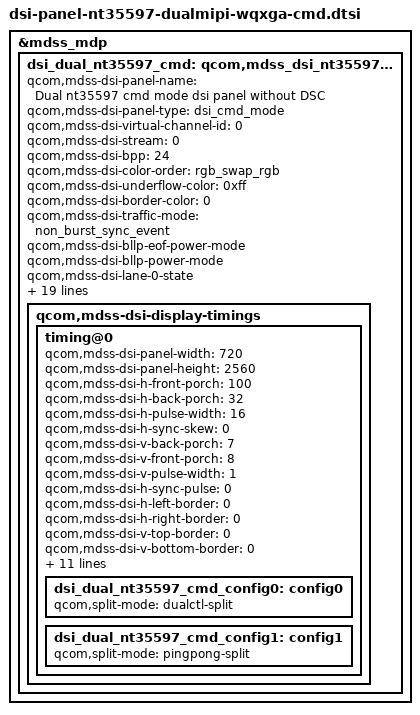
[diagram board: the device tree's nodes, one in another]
/* Copyright (c) 2015-2017, The Linux Foundation. All rights reserved.
 *
 * This program is free software; you can redistribute it and/or modify
 * it under the terms of the GNU General Public License version 2 and
 * only version 2 as published by the Free Software Foundation.
 *
 * This program is distributed in the hope that it will be useful,
 * but WITHOUT ANY WARRANTY; without even the implied warranty of
 * MERCHANTABILITY or FITNESS FOR A PARTICULAR PURPOSE.  See the
 * GNU General Public License for more details.
 */

&mdss_mdp {
	dsi_dual_nt35597_cmd: qcom,mdss_dsi_nt35597_wqxga_cmd{
		qcom,mdss-dsi-panel-name =
			"Dual nt35597 cmd mode dsi panel without DSC";
		qcom,mdss-dsi-panel-type = "dsi_cmd_mode";
		qcom,mdss-dsi-virtual-channel-id = <0>;
		qcom,mdss-dsi-stream = <0>;
		qcom,mdss-dsi-bpp = <24>;
		qcom,mdss-dsi-color-order = "rgb_swap_rgb";
		qcom,mdss-dsi-underflow-color = <0xff>;
		qcom,mdss-dsi-border-color = <0>;
		qcom,mdss-dsi-traffic-mode = "non_burst_sync_event";
		qcom,mdss-dsi-bllp-eof-power-mode;
		qcom,mdss-dsi-bllp-power-mode;
		qcom,mdss-dsi-lane-0-state;
		qcom,mdss-dsi-lane-1-state;
		qcom,mdss-dsi-lane-2-state;
		qcom,mdss-dsi-lane-3-state;
		qcom,adjust-timer-wakeup-ms = <1>;
		qcom,mdss-dsi-reset-sequence = <1 10>, <0 10>, <1 10>;
		qcom,mdss-pan-physical-width-dimension = <74>;
		qcom,mdss-pan-physical-height-dimension = <131>;
		qcom,mdss-dsi-t-clk-post = <0x0d>;
		qcom,mdss-dsi-t-clk-pre = <0x2d>;
		qcom,mdss-dsi-bl-max-level = <4095>;
		qcom,mdss-dsi-dma-trigger = "trigger_sw";
		qcom,mdss-dsi-mdp-trigger = "none";
		qcom,mdss-dsi-te-pin-select = <1>;
		qcom,mdss-dsi-wr-mem-start = <0x2c>;
		qcom,mdss-dsi-wr-mem-continue = <0x3c>;
		qcom,mdss-dsi-te-dcs-command = <1>;
		qcom,mdss-dsi-te-check-enable;
		qcom,mdss-dsi-te-using-te-pin;
		qcom,ulps-enabled;

		qcom,mdss-dsi-display-timings {
			timing@0{
				qcom,mdss-dsi-panel-width = <720>;
				qcom,mdss-dsi-panel-height = <2560>;
				qcom,mdss-dsi-h-front-porch = <100>;
				qcom,mdss-dsi-h-back-porch = <32>;
				qcom,mdss-dsi-h-pulse-width = <16>;
				qcom,mdss-dsi-h-sync-skew = <0>;
				qcom,mdss-dsi-v-back-porch = <7>;
				qcom,mdss-dsi-v-front-porch = <8>;
				qcom,mdss-dsi-v-pulse-width = <1>;
				qcom,mdss-dsi-h-sync-pulse = <0>;
				qcom,mdss-dsi-h-left-border = <0>;
				qcom,mdss-dsi-h-right-border = <0>;
				qcom,mdss-dsi-v-top-border = <0>;
				qcom,mdss-dsi-v-bottom-border = <0>;
				qcom,mdss-dsi-panel-framerate = <60>;
				qcom,mdss-dsi-on-command =
					[15 01 00 00 10 00 02 ff 10
					15 01 00 00 10 00 02 fb 01
					15 01 00 00 10 00 02 ba 03
					15 01 00 00 10 00 02 e5 01
					15 01 00 00 10 00 02 35 00
					15 01 00 00 10 00 02 bb 10
					15 01 00 00 10 00 02 b0 03
					15 01 00 00 10 00 02 ff e0
					15 01 00 00 10 00 02 fb 01
					15 01 00 00 10 00 02 6b 3d
					15 01 00 00 10 00 02 6c 3d
					15 01 00 00 10 00 02 6d 3d
					15 01 00 00 10 00 02 6e 3d
					15 01 00 00 10 00 02 6f 3d
					15 01 00 00 10 00 02 35 02
					15 01 00 00 10 00 02 36 72
					15 01 00 00 10 00 02 37 10
					15 01 00 00 10 00 02 08 c0
					15 01 00 00 10 00 02 ff 24
					15 01 00 00 10 00 02 fb 01
					15 01 00 00 10 00 02 c6 06
					15 01 00 00 10 00 02 ff 10
					05 01 00 00 a0 00 02 11 00
					05 01 00 00 a0 00 02 29 00];

				qcom,mdss-dsi-off-command = [05 01 00 00 0a 00
					02 28 00 05 01 00 00 3c 00 02 10 00];

				qcom,mdss-dsi-on-command-state = "dsi_lp_mode";
				qcom,mdss-dsi-off-command-state = "dsi_hs_mode";
				qcom,mdss-dsi-panel-timings = [cd 32 22 00 60
					64 26 34 29 03 04 00];

				qcom,config-select =
					<&dsi_dual_nt35597_cmd_config0>;

				dsi_dual_nt35597_cmd_config0: config0 {
					qcom,split-mode = "dualctl-split";
				};

				dsi_dual_nt35597_cmd_config1: config1 {
					qcom,split-mode = "pingpong-split";
				};
			};
		};
	};
};
